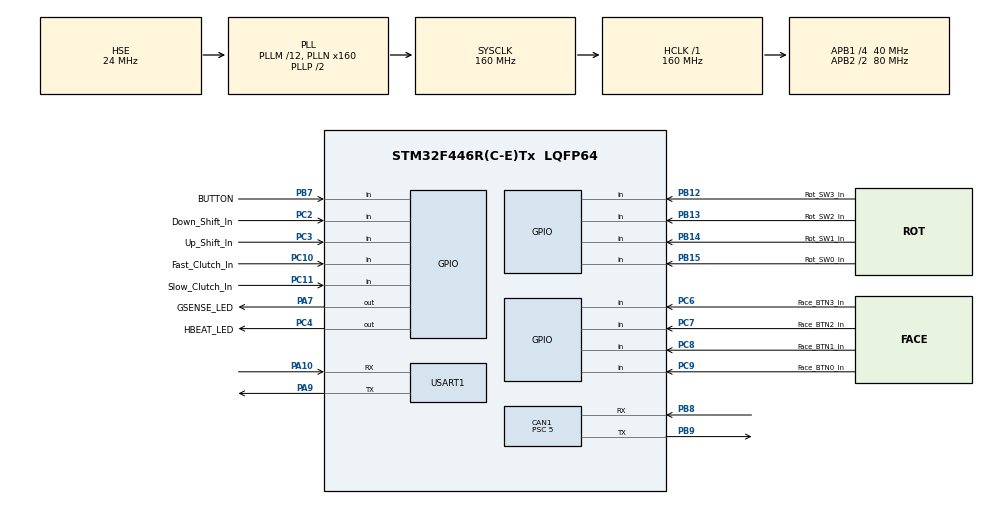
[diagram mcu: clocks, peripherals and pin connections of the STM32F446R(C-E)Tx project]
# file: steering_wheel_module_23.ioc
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CAN1.ABOM=ENABLE
CAN1.AWUM=ENABLE
CAN1.BS1=CAN_BS1_6TQ
CAN1.BS2=CAN_BS2_1TQ
CAN1.CalculateBaudRate=1000000
CAN1.CalculateTimeBit=1000
CAN1.CalculateTimeQuantum=125.0
CAN1.Prescaler=5
FREERTOS.MEMORY_ALLOCATION=2
FREERTOS.Tasks01=main_task,0,1024,task_MainTask,Default,NULL,Static,main_taskBuffer,main_taskControlBlock;buffer_handling,1,1024,task_BufferHandling,Default,NULL,Static,buffer_handlingBuffer,buffer_handlingControlBlock
FREERTOS.configENABLE_FPU=1
FREERTOS.configMINIMAL_STACK_SIZE=512
Mcu.Family=STM32F4
Mcu.Name=STM32F446R(C-E)Tx
Mcu.Package=LQFP64
NVIC.CAN1_RX0_IRQn=true\:5\:0\:false\:false\:true\:true\:true\:true\:true
NVIC.CAN1_RX1_IRQn=true\:5\:0\:false\:false\:true\:true\:true\:true\:true
NVIC.CAN1_TX_IRQn=true\:5\:0\:false\:false\:true\:true\:true\:true\:true
NVIC.PriorityGroup=NVIC_PRIORITYGROUP_4
NVIC.TIM6_DAC_IRQn=true\:15\:0\:false\:false\:true\:false\:false\:true\:true
NVIC.TimeBase=TIM6_DAC_IRQn
NVIC.TimeBaseIP=TIM6
PA10.Mode=Asynchronous
PA10.Signal=USART1_RX
PA7.GPIO_Label=GSENSE_LED
PA7.Signal=GPIO_Output
PA9.Mode=Asynchronous
PA9.Signal=USART1_TX
PB12.GPIO_Label=Rot_SW3_In
PB12.Signal=GPIO_Input
PB13.GPIO_Label=Rot_SW2_In
PB13.Signal=GPIO_Input
PB14.GPIO_Label=Rot_SW1_In
PB14.Signal=GPIO_Input
PB15.GPIO_Label=Rot_SW0_In
PB15.Signal=GPIO_Input
PB7.GPIO_Label=BUTTON
PB7.Signal=GPIO_Input
PB8.Mode=CAN_Activate
PB8.Signal=CAN1_RX
PB9.Mode=CAN_Activate
PB9.Signal=CAN1_TX
PC10.GPIO_Label=Fast_Clutch_In
PC10.Signal=GPIO_Input
PC11.GPIO_Label=Slow_Clutch_In
PC11.Signal=GPIO_Input
PC2.GPIO_Label=Down_Shift_In
PC2.Signal=GPIO_Input
PC3.GPIO_Label=Up_Shift_In
PC3.Signal=GPIO_Input
PC4.GPIO_Label=HBEAT_LED
PC4.Signal=GPIO_Output
PC6.GPIO_Label=Face_BTN3_In
PC6.Signal=GPIO_Input
PC7.GPIO_Label=Face_BTN2_In
PC7.Signal=GPIO_Input
PC8.GPIO_Label=Face_BTN1_In
PC8.Signal=GPIO_Input
PC9.GPIO_Label=Face_BTN0_In
PC9.Signal=GPIO_Input
PH0-OSC_IN.Mode=HSE-External-Clock-Source
PH0-OSC_IN.Signal=RCC_OSC_IN
PH1-OSC_OUT.Mode=HSE-External-Clock-Source
PH1-OSC_OUT.Signal=RCC_OSC_OUT
ProjectManager.HeapSize=0x200
ProjectManager.StackSize=0x400
ProjectManager.TargetToolchain=STM32CubeIDE
RCC.AHBFreq_Value=160000000
RCC.APB1CLKDivider=RCC_HCLK_DIV4
RCC.APB1Freq_Value=40000000
RCC.APB1TimFreq_Value=80000000
RCC.APB2CLKDivider=RCC_HCLK_DIV2
RCC.APB2Freq_Value=80000000
RCC.APB2TimFreq_Value=160000000
RCC.CortexFreq_Value=160000000
RCC.HCLKFreq_Value=160000000
RCC.HSE_VALUE=24000000
RCC.PLLM=12
RCC.PLLN=160
RCC.PLLSourceVirtual=RCC_PLLSOURCE_HSE
RCC.SYSCLKFreq_VALUE=160000000
RCC.SYSCLKSource=RCC_SYSCLKSOURCE_PLLCLK
RCC.USBFreq_Value=160000000
RCC.VCOOutputFreq_Value=320000000
USART1.VirtualMode=VM_ASYNC
VP_FREERTOS_VS_CMSIS_V1.Mode=CMSIS_V1
VP_SYS_VS_tim6.Mode=TIM6
board=custom

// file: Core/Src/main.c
/* USER CODE BEGIN Header */
/**
  ******************************************************************************
  * @file           : main.c
  * @brief          : Main program body
  ******************************************************************************
  * @attention
  *
  * Copyright (c) 2022 STMicroelectronics.
  * All rights reserved.
  *
  * This software is licensed under terms that can be found in the LICENSE file
  * in the root directory of this software component.
  * If no LICENSE file comes with this software, it is provided AS-IS.
  *
  ******************************************************************************
  */
/* USER CODE END Header */
#include "main.h"
#include "cmsis_os.h"

/* USER CODE BEGIN Includes */
#include "gopher_sense.h"
#include "steering_wheel.h"
/* USER CODE END Includes */

CAN_HandleTypeDef hcan1;

UART_HandleTypeDef huart1;

osThreadId main_taskHandle;
uint32_t main_taskBuffer[ 1024 ];
osStaticThreadDef_t main_taskControlBlock;
osThreadId buffer_handlingHandle;
uint32_t buffer_handlingBuffer[ 1024 ];
osStaticThreadDef_t buffer_handlingControlBlock;

void SystemClock_Config(void);
static void MX_GPIO_Init(void);
static void MX_CAN1_Init(void);
static void MX_USART1_UART_Init(void);
void task_MainTask(void const * argument);
void task_BufferHandling(void const * argument);

int main(void)
{

  /* MCU Configuration--------------------------------------------------------*/

  /* Reset of all peripherals, Initializes the Flash interface and the Systick. */
  HAL_Init();

  /* Configure the system clock */
  SystemClock_Config();

  /* Initialize all configured peripherals */
  MX_GPIO_Init();
  MX_CAN1_Init();
  MX_USART1_UART_Init();
  /* USER CODE BEGIN 2 */

  init(&hcan1);
  gsense_init(&hcan1, GSENSE_LED_GPIO_Port, GSENSE_LED_Pin);
  /* USER CODE END 2 */

  /* Create the thread(s) */
  /* definition and creation of main_task */
  osThreadStaticDef(main_task, task_MainTask, osPriorityNormal, 0, 1024, main_taskBuffer, &main_taskControlBlock);
  main_taskHandle = osThreadCreate(osThread(main_task), NULL);

  /* definition and creation of buffer_handling */
  osThreadStaticDef(buffer_handling, task_BufferHandling, osPriorityAboveNormal, 0, 1024, buffer_handlingBuffer, &buffer_handlingControlBlock);
  buffer_handlingHandle = osThreadCreate(osThread(buffer_handling), NULL);

  /* Start scheduler */
  osKernelStart();

  /* We should never get here as control is now taken by the scheduler */
  /* Infinite loop */
  while (1)
  {

  }
}

void SystemClock_Config(void)
{
  RCC_OscInitTypeDef RCC_OscInitStruct = {0};
  RCC_ClkInitTypeDef RCC_ClkInitStruct = {0};

  /** Configure the main internal regulator output voltage
  */
  __HAL_RCC_PWR_CLK_ENABLE();
  __HAL_PWR_VOLTAGESCALING_CONFIG(PWR_REGULATOR_VOLTAGE_SCALE1);

  /** Initializes the RCC Oscillators according to the specified parameters
  * in the RCC_OscInitTypeDef structure.
  */
  RCC_OscInitStruct.OscillatorType = RCC_OSCILLATORTYPE_HSE;
  RCC_OscInitStruct.HSEState = RCC_HSE_BYPASS;
  RCC_OscInitStruct.PLL.PLLState = RCC_PLL_ON;
  RCC_OscInitStruct.PLL.PLLSource = RCC_PLLSOURCE_HSE;
  RCC_OscInitStruct.PLL.PLLM = 12;
  RCC_OscInitStruct.PLL.PLLN = 160;
  RCC_OscInitStruct.PLL.PLLP = RCC_PLLP_DIV2;
  RCC_OscInitStruct.PLL.PLLQ = 2;
  RCC_OscInitStruct.PLL.PLLR = 2;
  if (HAL_RCC_OscConfig(&RCC_OscInitStruct) != HAL_OK)
  {
    Error_Handler();
  }

  /** Initializes the CPU, AHB and APB buses clocks
  */
  RCC_ClkInitStruct.ClockType = RCC_CLOCKTYPE_HCLK|RCC_CLOCKTYPE_SYSCLK
                              |RCC_CLOCKTYPE_PCLK1|RCC_CLOCKTYPE_PCLK2;
  RCC_ClkInitStruct.SYSCLKSource = RCC_SYSCLKSOURCE_PLLCLK;
  RCC_ClkInitStruct.AHBCLKDivider = RCC_SYSCLK_DIV1;
  RCC_ClkInitStruct.APB1CLKDivider = RCC_HCLK_DIV4;
  RCC_ClkInitStruct.APB2CLKDivider = RCC_HCLK_DIV2;

  if (HAL_RCC_ClockConfig(&RCC_ClkInitStruct, FLASH_LATENCY_5) != HAL_OK)
  {
    Error_Handler();
  }
}

static void MX_CAN1_Init(void)
{

  hcan1.Instance = CAN1;
  hcan1.Init.Prescaler = 5;
  hcan1.Init.Mode = CAN_MODE_NORMAL;
  hcan1.Init.SyncJumpWidth = CAN_SJW_1TQ;
  hcan1.Init.TimeSeg1 = CAN_BS1_6TQ;
  hcan1.Init.TimeSeg2 = CAN_BS2_1TQ;
  hcan1.Init.TimeTriggeredMode = DISABLE;
  hcan1.Init.AutoBusOff = ENABLE;
  hcan1.Init.AutoWakeUp = ENABLE;
  hcan1.Init.AutoRetransmission = DISABLE;
  hcan1.Init.ReceiveFifoLocked = DISABLE;
  hcan1.Init.TransmitFifoPriority = DISABLE;
  if (HAL_CAN_Init(&hcan1) != HAL_OK)
  {
    Error_Handler();
  }

}

static void MX_USART1_UART_Init(void)
{

  huart1.Instance = USART1;
  huart1.Init.BaudRate = 115200;
  huart1.Init.WordLength = UART_WORDLENGTH_8B;
  huart1.Init.StopBits = UART_STOPBITS_1;
  huart1.Init.Parity = UART_PARITY_NONE;
  huart1.Init.Mode = UART_MODE_TX_RX;
  huart1.Init.HwFlowCtl = UART_HWCONTROL_NONE;
  huart1.Init.OverSampling = UART_OVERSAMPLING_16;
  if (HAL_UART_Init(&huart1) != HAL_OK)
  {
    Error_Handler();
  }

}

static void MX_GPIO_Init(void)
{
  GPIO_InitTypeDef GPIO_InitStruct = {0};

  /* GPIO Ports Clock Enable */
  __HAL_RCC_GPIOH_CLK_ENABLE();
  __HAL_RCC_GPIOC_CLK_ENABLE();
  __HAL_RCC_GPIOA_CLK_ENABLE();
  __HAL_RCC_GPIOB_CLK_ENABLE();

  /*Configure GPIO pin Output Level */
  HAL_GPIO_WritePin(GSENSE_LED_GPIO_Port, GSENSE_LED_Pin, GPIO_PIN_RESET);

  /*Configure GPIO pin Output Level */
  HAL_GPIO_WritePin(HBEAT_LED_GPIO_Port, HBEAT_LED_Pin, GPIO_PIN_RESET);

  /*Configure GPIO pins : Down_Shift_In_Pin Up_Shift_In_Pin Face_BTN3_In_Pin Face_BTN2_In_Pin
                           Face_BTN1_In_Pin Face_BTN0_In_Pin Fast_Clutch_In_Pin Slow_Clutch_In_Pin */
  GPIO_InitStruct.Pin = Down_Shift_In_Pin|Up_Shift_In_Pin|Face_BTN3_In_Pin|Face_BTN2_In_Pin
                          |Face_BTN1_In_Pin|Face_BTN0_In_Pin|Fast_Clutch_In_Pin|Slow_Clutch_In_Pin;
  GPIO_InitStruct.Mode = GPIO_MODE_INPUT;
  GPIO_InitStruct.Pull = GPIO_NOPULL;
  HAL_GPIO_Init(GPIOC, &GPIO_InitStruct);

  /*Configure GPIO pin : GSENSE_LED_Pin */
  GPIO_InitStruct.Pin = GSENSE_LED_Pin;
  GPIO_InitStruct.Mode = GPIO_MODE_OUTPUT_PP;
  GPIO_InitStruct.Pull = GPIO_NOPULL;
  GPIO_InitStruct.Speed = GPIO_SPEED_FREQ_LOW;
  HAL_GPIO_Init(GSENSE_LED_GPIO_Port, &GPIO_InitStruct);

  /*Configure GPIO pin : HBEAT_LED_Pin */
  GPIO_InitStruct.Pin = HBEAT_LED_Pin;
  GPIO_InitStruct.Mode = GPIO_MODE_OUTPUT_PP;
  GPIO_InitStruct.Pull = GPIO_NOPULL;
  GPIO_InitStruct.Speed = GPIO_SPEED_FREQ_LOW;
  HAL_GPIO_Init(HBEAT_LED_GPIO_Port, &GPIO_InitStruct);

  /*Configure GPIO pins : Rot_SW3_In_Pin Rot_SW2_In_Pin Rot_SW1_In_Pin Rot_SW0_In_Pin
                           BUTTON_Pin */
  GPIO_InitStruct.Pin = Rot_SW3_In_Pin|Rot_SW2_In_Pin|Rot_SW1_In_Pin|Rot_SW0_In_Pin
                          |BUTTON_Pin;
  GPIO_InitStruct.Mode = GPIO_MODE_INPUT;
  GPIO_InitStruct.Pull = GPIO_NOPULL;
  HAL_GPIO_Init(GPIOB, &GPIO_InitStruct);

}

void task_MainTask(void const * argument)
{
  /* USER CODE BEGIN 5 */
  /* Infinite loop */
  for(;;)
  {
	  main_loop();
    osDelay(1);
  }
  /* USER CODE END 5 */
}

void task_BufferHandling(void const * argument)
{
  /* USER CODE BEGIN task_BufferHandling */
  /* Infinite loop */
  for(;;)
  {
	  can_buffer_handling_loop();
    osDelay(1);
  }
  /* USER CODE END task_BufferHandling */
}

void HAL_TIM_PeriodElapsedCallback(TIM_HandleTypeDef *htim)
{
  if (htim->Instance == TIM6) {
    HAL_IncTick();
  }
  /* USER CODE BEGIN Callback 1 */
  else{
	  //DAQ_TimerCallback(htim);
  }
  /* USER CODE END Callback 1 */
}

void Error_Handler(void)
{
  __disable_irq();
  while (1)
  {
  }
}
